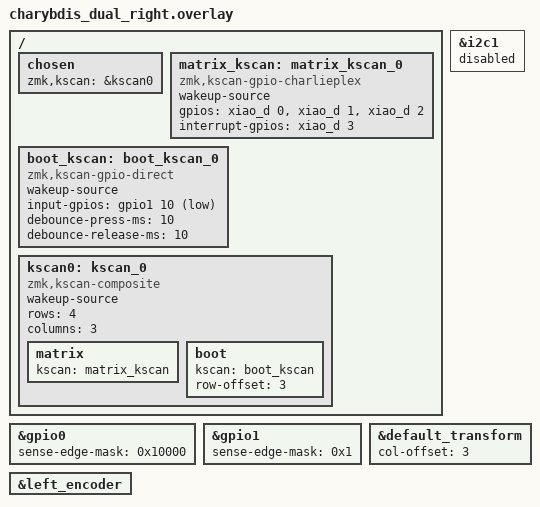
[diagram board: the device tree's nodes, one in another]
#include "charybdis_dual.dtsi"

#include <zephyr/dt-bindings/gpio/gpio.h>


/*
 * ============================================================
 * Encoder wake
 *
 * D4 = P0.4
 * D5 = P0.5
 * ============================================================
 */

&gpio0 {
    sense-edge-mask = <0x10000>;
};

&gpio1 {
    sense-edge-mask = <0x1>;
};

&i2c1 {
    status = "disabled";
};


/ {
    chosen {
        zmk,kscan = &kscan0;
    };


    /*
     * ========================================================
     * 通常キー Charlieplex
     *
     * D0 / D1 / D2 = Matrix
     * D3 = Key Wake Interrupt
     * ========================================================
     */

    matrix_kscan: matrix_kscan_0 {
        compatible = "zmk,kscan-gpio-charlieplex";
        wakeup-source;

        gpios =
            <&xiao_d 0 GPIO_ACTIVE_HIGH>,
            <&xiao_d 1 GPIO_ACTIVE_HIGH>,
            <&xiao_d 2 GPIO_ACTIVE_HIGH>;

        interrupt-gpios =
            <&xiao_d 3 (GPIO_ACTIVE_HIGH | GPIO_PULL_DOWN)>;
    };


    /*
     * ========================================================
     * 専用BOOTボタン
     *
     * D6 ---- push button ---- GND
     * ========================================================
     */

    boot_kscan: boot_kscan_0 {
        compatible = "zmk,kscan-gpio-direct";
        wakeup-source;

        input-gpios =
            <&gpio1 10 (GPIO_ACTIVE_LOW | GPIO_PULL_UP)>;

        debounce-press-ms = <10>;
        debounce-release-ms = <10>;
    };


    /*
     * Charlieplex + BOOT
     */
    kscan0: kscan_0 {
        compatible = "zmk,kscan-composite";
        wakeup-source;

        rows = <4>;
        columns = <3>;

        matrix {
            kscan = <&matrix_kscan>;
        };

        boot {
            kscan = <&boot_kscan>;
            row-offset = <3>;
        };
    };
};


/*
 * 右半分をglobal column 3～5へ配置。
 *
 * BOOTも
 * local RC(3,0)
 *       ↓
 * global RC(3,3)
 */
&default_transform {
    col-offset = <3>;
};


/*
 * Encoder
 *
 * D4 = A
 * D5 = B
 */
&left_encoder {
    status = "okay";
};
